# STM32F101xx register map
File version: 1.1
CPU: 
Registers are 32-bit, read-write, reset 0x0 unless marked. A register's access mark holds for its fields unless they carry their own. Offsets are from the block's base; [hi:lo] are bit positions; lines under a group give offsets from that group; {n}, {i} and the like mark numbered series.

## BKP — Backup registers
Base 0x40006C04
0x00 DR1 — Backup data register (BKP_DR)
  [15:0] D1 — Backup data
0x04 DR2 — Backup data register (BKP_DR)
  [15:0] D2 — Backup data
0x08 DR3 — Backup data register (BKP_DR)
  [15:0] D3 — Backup data
0x0C DR4 — Backup data register (BKP_DR)
  [15:0] D4 — Backup data
0x10 DR5 — Backup data register (BKP_DR)
  [15:0] D5 — Backup data
0x14 DR6 — Backup data register (BKP_DR)
  [15:0] D6 — Backup data
0x18 DR7 — Backup data register (BKP_DR)
  [15:0] D7 — Backup data
0x1C DR8 — Backup data register (BKP_DR)
  [15:0] D8 — Backup data
0x20 DR9 — Backup data register (BKP_DR)
  [15:0] D9 — Backup data
0x24 DR10 — Backup data register (BKP_DR)
  [15:0] D10 — Backup data
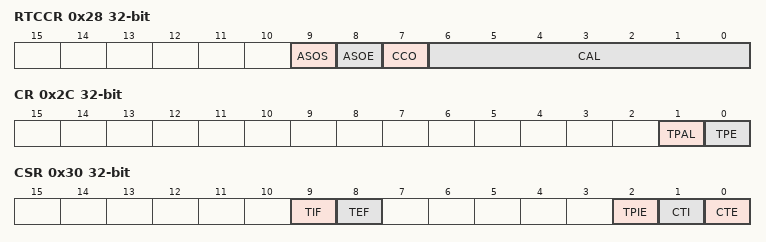
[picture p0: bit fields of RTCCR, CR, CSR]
0x28 RTCCR — RTC clock calibration register (BKP_RTCCR)
  [9] ASOS — Alarm or second output selection
  [8] ASOE — Alarm or second output enable
  [7] CCO — Calibration Clock Output
  [6:0] CAL — Calibration value
0x2C CR — Backup control register (BKP_CR)
  [1] TPAL — Tamper pin active level
  [0] TPE — Tamper pin enable
0x30 CSR access per field — BKP_CSR control/status register (BKP_CSR)
  [9] TIF ro — Tamper Interrupt Flag
  [8] TEF ro — Tamper Event Flag
  [2] TPIE rw — Tamper Pin interrupt enable
  [1] CTI wo — Clear Tamper Interrupt
  [0] CTE wo — Clear Tamper event
{0x10+4i} DR{i} (i=11..13) — Backup data register (BKP_DR)
  [15:0] DR{i} — Backup data
{0x10+4i} DR{i} (i=14..42) — Backup data register (BKP_DR)
  [15:0] D{i} — Backup data

## ADC1 — Analog to digital converter
Base 0x40012400
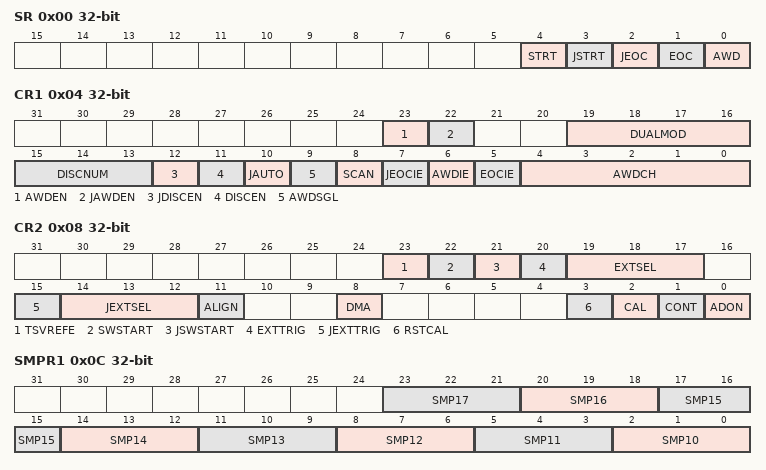
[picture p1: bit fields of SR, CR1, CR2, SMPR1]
0x00 SR — status register
  [4] STRT — Regular channel start flag
  [3] JSTRT — Injected channel start flag
  [2] JEOC — Injected channel end of conversion
  [1] EOC — Regular channel end of conversion
  [0] AWD — Analog watchdog flag
0x04 CR1 — control register 1
  [23] AWDEN — Analog watchdog enable on regular channels
  [22] JAWDEN — Analog watchdog enable on injected channels
  [19:16] DUALMOD — Dual mode selection
  [15:13] DISCNUM — Discontinuous mode channel count
  [12] JDISCEN — Discontinuous mode on injected channels
  [11] DISCEN — Discontinuous mode on regular channels
  [10] JAUTO — Automatic injected group conversion
  [9] AWDSGL — Enable the watchdog on a single channel in scan mode
  [8] SCAN — Scan mode
  [7] JEOCIE — Interrupt enable for injected channels
  [6] AWDIE — Analog watchdog interrupt enable
  [5] EOCIE — Interrupt enable for EOC
  [4:0] AWDCH — Analog watchdog channel select bits
0x08 CR2 — control register 2
  [23] TSVREFE — Temperature sensor and VREFINT enable
  [22] SWSTART — Start conversion of regular channels
  [21] JSWSTART — Start conversion of injected channels
  [20] EXTTRIG — External trigger conversion mode for regular channels
  [19:17] EXTSEL — External event select for regular group
  [15] JEXTTRIG — External trigger conversion mode for injected channels
  [14:12] JEXTSEL — External event select for injected group
  [11] ALIGN — Data alignment
  [8] DMA — Direct memory access mode
  [3] RSTCAL — Reset calibration
  [2] CAL — A/D calibration
  [1] CONT — Continuous conversion
  [0] ADON — A/D converter ON / OFF
0x0C SMPR1 — sample time register 1
  [3n-28:3n-30] SMP{n} (n=10..17) — Channel {n} sample time selection
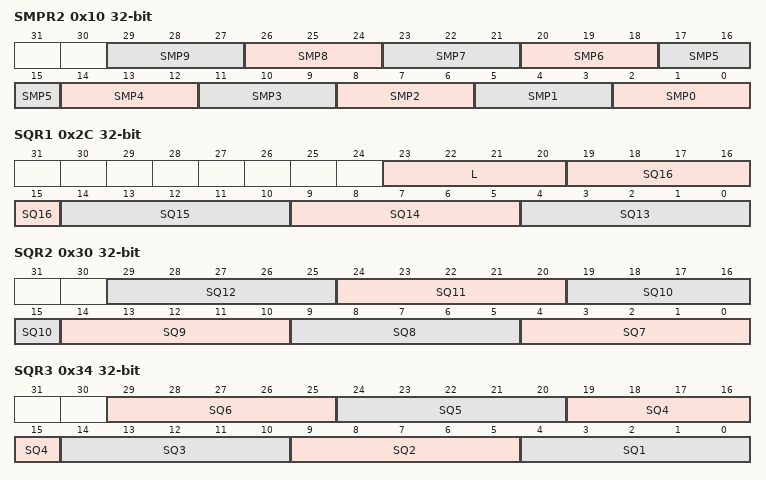
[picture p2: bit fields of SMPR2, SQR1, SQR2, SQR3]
0x10 SMPR2 — sample time register 2
  [3n+2:3n] SMP{n} (n=0..9) — Channel {n} sample time selection
{0x10+4i} JOFR{i} (i=1..4) — injected channel data offset register x
  [11:0] JOFFSET{i} — Data offset for injected channel x
0x24 HTR reset 0xFFF — watchdog higher threshold register
  [11:0] HT — Analog watchdog higher threshold
0x28 LTR — watchdog lower threshold register
  [11:0] LT — Analog watchdog lower threshold
0x2C SQR1 — regular sequence register 1
  [23:20] L — Regular channel sequence length
  [5n-61:5n-65] SQ{n} (n=13..16) — {n}th conversion in regular sequence
0x30 SQR2 — regular sequence register 2
  [5n-31:5n-35] SQ{n} (n=7..12) — {n}th conversion in regular sequence
0x34 SQR3 — regular sequence register 3
  [29:25] SQ6 — 6th conversion in regular sequence
  [24:20] SQ5 — 5th conversion in regular sequence
  [19:15] SQ4 — 4th conversion in regular sequence
  [14:10] SQ3 — 3rd conversion in regular sequence
  [9:5] SQ2 — 2nd conversion in regular sequence
  [4:0] SQ1 — 1st conversion in regular sequence
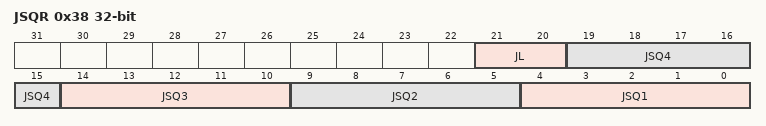
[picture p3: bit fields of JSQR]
0x38 JSQR — injected sequence register
  [21:20] JL — Injected sequence length
  [19:15] JSQ4 — 4th conversion in injected sequence
  [14:10] JSQ3 — 3rd conversion in injected sequence
  [9:5] JSQ2 — 2nd conversion in injected sequence
  [4:0] JSQ1 — 1st conversion in injected sequence
{0x38+4i} JDR{i} ro (i=1..4) — injected data register x
  [15:0] JDATA — Injected data
0x4C DR ro — regular data register
  [15:0] DATA — Regular data

## NVIC — Nested Vectored Interrupt Controller
Base 0xE000E000
0x04 ICTR ro — Interrupt Controller Type Register
  [3:0] INTLINESNUM — Total number of interrupt lines in groups
0x100 ISER0 — Interrupt Set-Enable Register
  [31:0] SETENA
0x104 ISER1 — Interrupt Set-Enable Register
  [31:0] SETENA
0x180 ICER0 — Interrupt Clear-Enable Register
  [31:0] CLRENA
0x184 ICER1 — Interrupt Clear-Enable Register
  [31:0] CLRENA
0x200 ISPR0 — Interrupt Set-Pending Register
  [31:0] SETPEND
0x204 ISPR1 — Interrupt Set-Pending Register
  [31:0] SETPEND
0x280 ICPR0 — Interrupt Clear-Pending Register
  [31:0] CLRPEND
0x284 ICPR1 — Interrupt Clear-Pending Register
  [31:0] CLRPEND
0x300 IABR0 ro — Interrupt Active Bit Register
  [31:0] ACTIVE
0x304 IABR1 ro — Interrupt Active Bit Register
  [31:0] ACTIVE
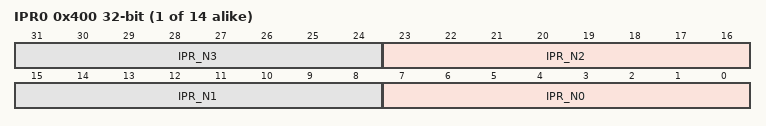
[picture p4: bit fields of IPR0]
{0x400+4i} IPR{i} (i=0..13) — Interrupt Priority Register
  [8n+7:8n] IPR_N{n} (n=0..3)
0xF00 STIR wo — Software Triggered Interrupt Register
  [8:0] INTID — interrupt to be triggered
